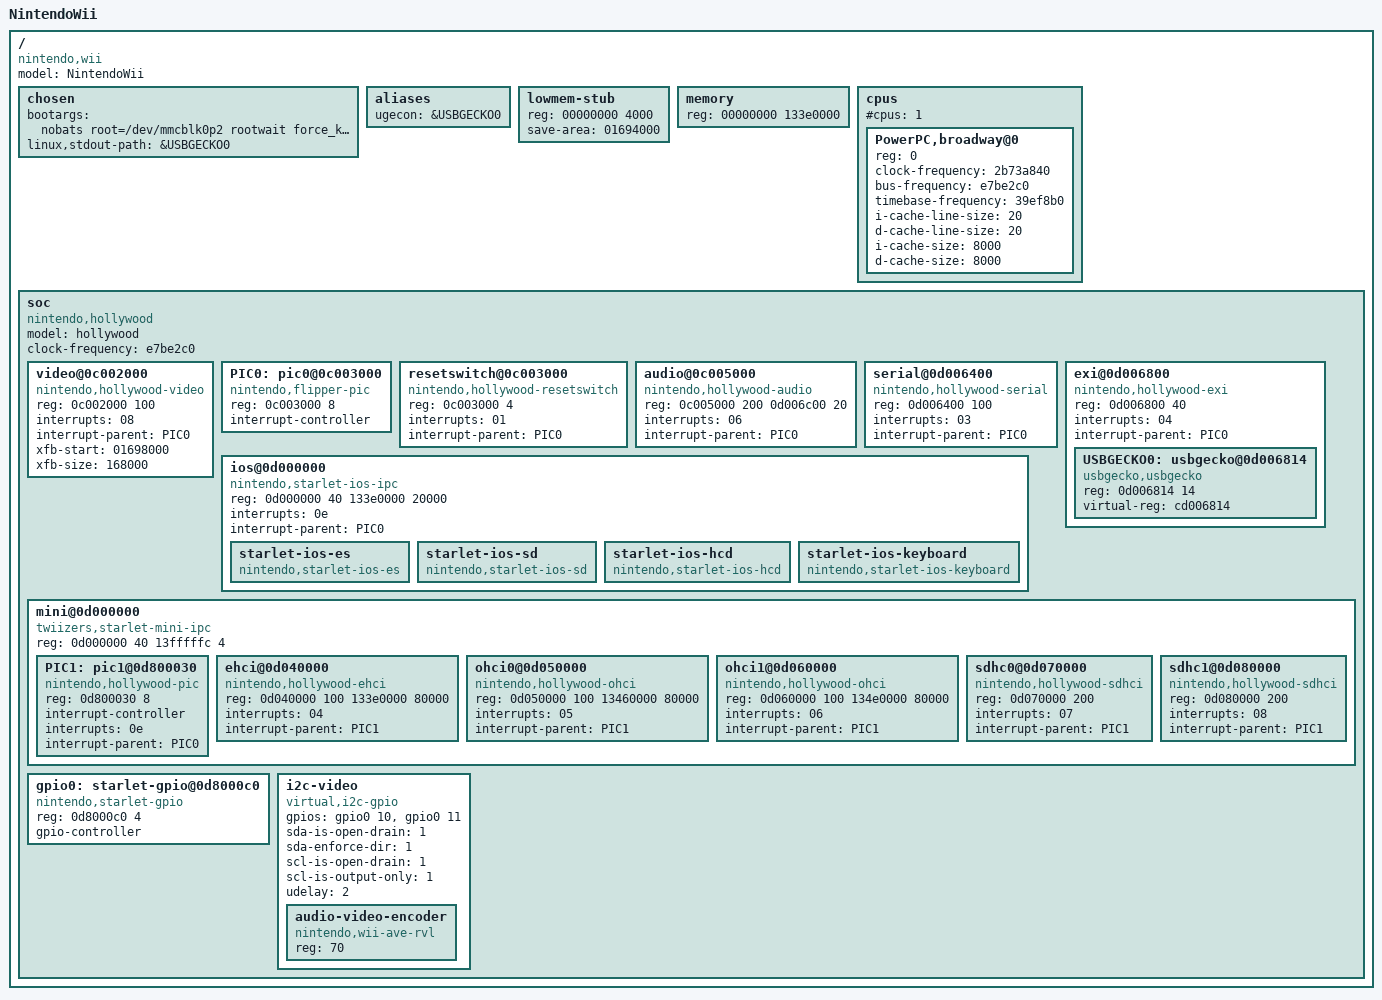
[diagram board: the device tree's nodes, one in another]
/*
 * arch/powerpc/boot/dts/wii.dts
 *
 * Nintendo Wii platform device tree source
 * Copyright (C) 2008-2009 The GameCube Linux Team
 * Copyright (C) 2008,2009 Albert Herranz
 *
 * This program is free software; you can redistribute it and/or
 * modify it under the terms of the GNU General Public License
 * as published by the Free Software Foundation; either version 2
 * of the License, or (at your option) any later version.
 *
 */


/memreserve/ 01694000-01697fff; /* lowmem stub save area */
/memreserve/ 01698000-017fffff;	/* framebuffer, see video@0c002000 */
/memreserve/ 01800000-0fffffff;	/* memory hole */
/memreserve/ 10000000-10003fff;	/* DSP */

/ {
	model = "NintendoWii";
	compatible = "nintendo,wii";
	#address-cells = <1>;
	#size-cells = <1>;

	chosen {
		/* ramdisk */
		/* bootargs = "nobats root=/dev/ram0 video=gcnfb ip=on force_keyboard_port=4"; */

		/* nfsroot */
		/* bootargs = "nobats root=/dev/nfs nfsroot=192.168.001.253:/nfsroot/cube ip=on video=gcnfb:tv=NTSC force_keyboard_port=4"; */

		/* root filesystem on 2nd partition of SD card, whiite style  */
		bootargs = "nobats root=/dev/mmcblk0p2 rootwait force_keyboard_port=4 video=gcnfb:60Hz,tv=NTSC placeholder_for_additional_kernel_options_targetted_at_hexedit_lovers";
		linux,stdout-path = &USBGECKO0;
	};

	aliases {
		ugecon = &USBGECKO0;
	};

	lowmem-stub {
		reg = <00000000 4000>;
		save-area = <01694000>;	/* must be memreserve'd */
	};

	memory {
		device_type = "memory";
		/* mem1 + hole + mem2 - ioh */
		reg = <00000000 133e0000>;
	};

	cpus {
		#cpus = <1>;
		#address-cells = <1>;
		#size-cells = <0>;

		PowerPC,broadway@0 {
			device_type = "cpu";
			reg = <0>;
			clock-frequency = <2b73a840>; /* 729MHz */
			bus-frequency = <e7be2c0>; /* 243MHz core-to-bus 3x */
			timebase-frequency = <39ef8b0>; /* 243MHz / 4 */
			/* Following required by dtc but not used */
			i-cache-line-size = <20>;
			d-cache-line-size = <20>;
			i-cache-size = <8000>;
			d-cache-size = <8000>;
		};
	};

	/* devices contained in the hollywood chipset */
	soc {
		#address-cells = <1>;
		#size-cells = <1>;
		#interrupt-cells = <1>;
		model = "hollywood";
		compatible = "nintendo,hollywood";
		clock-frequency = <e7be2c0>; /* 243MHz */
		ranges = <0c000000 0c000000 00010000
			  0d000000 0d000000 00010000
			  0d040000 0d040000 00050000
			  0d800000 0d800000 00001000
			  133e0000 133e0000 00c20000>;

		video@0c002000 {
			compatible = "nintendo,hollywood-video";
			reg = <0c002000 100>;
			interrupts = <08>;
			interrupt-parent = <&PIC0>;
			xfb-start = <01698000>; /* end-of-mem1 - xfb-size */
			xfb-size = <168000>;	/* 640x576x2 x 2 bytes */
		};

		PIC0: pic0@0c003000 {
			#interrupt-cells = <1>;
			compatible = "nintendo,flipper-pic";
			reg = <0c003000 8>;
			interrupt-controller;
		};

		resetswitch@0c003000 {
			compatible = "nintendo,hollywood-resetswitch";
			reg = <0c003000 4>;
			interrupts = <01>;
			interrupt-parent = <&PIC0>;
		};

		audio@0c005000 {
			compatible = "nintendo,hollywood-audio";
			reg = <0c005000 200	/* DSP */
			       0d006c00 20>;	/* AI */
			interrupts = <06>;
			interrupt-parent = <&PIC0>;
		};

		serial@0d006400 {
			compatible = "nintendo,hollywood-serial";
			reg = <0d006400 100>;
			interrupts = <03>;
			interrupt-parent = <&PIC0>;
		};

		/* External Interface bus */
		exi@0d006800 {
			#address-cells = <1>;
			#size-cells = <1>;
			compatible = "nintendo,hollywood-exi";
			reg = <0d006800 40>;
			interrupts = <04>;
			interrupt-parent = <&PIC0>;

			USBGECKO0: usbgecko@0d006814 {
				compatible = "usbgecko,usbgecko";
				reg = <0d006814 14>;
				virtual-reg = <cd006814>;
			};
		};

		/*
		 * Firmware interfaces accessible through Nintendo IOS IPC.
		 */
		ios@0d000000 {
			compatible = "nintendo,starlet-ios-ipc";
			reg = <0d000000 40	/* IPC */
			       133e0000 20000>;	/* MEM2 ioh 128K */
			interrupts = <0e>;
			interrupt-parent = <&PIC0>;

			starlet-ios-es {
				compatible = "nintendo,starlet-ios-es";
			};

			starlet-ios-sd {
				compatible = "nintendo,starlet-ios-sd";
			};

			starlet-ios-hcd {
				compatible = "nintendo,starlet-ios-hcd";
			};

			starlet-ios-keyboard {
				compatible = "nintendo,starlet-ios-keyboard";
			};
		};

		/*
		 * Hardware accessible through Team Twiizers 'mini' firmware
		 * replacement for Starlet.
		 */
		mini@0d000000 {
			#address-cells = <1>;
			#size-cells = <1>;
			#interrupt-cells = <1>;
			compatible = "twiizers,starlet-mini-ipc";
			reg = <0d000000 40	/* IPC */
			       13fffffc 4>;	/* mini header pointer */

			ranges = <0d040000 0d040000 00050000
				  0d800000 0d800000 00001000
				  133e0000 133e0000 00c20000>;

			PIC1: pic1@0d800030 {
				#interrupt-cells = <1>;
				compatible = "nintendo,hollywood-pic";
				reg = <0d800030 8>;
				interrupt-controller;
				interrupts = <0e>;
				interrupt-parent = <&PIC0>;
			};
			ehci@0d040000 {
				compatible = "nintendo,hollywood-ehci";
				reg = <0d040000 100
				       133e0000 80000>; /* 512 KB */
				interrupts = <04>;
				interrupt-parent = <&PIC1>;
			};
			ohci0@0d050000 {
				compatible = "nintendo,hollywood-ohci";
				reg = <0d050000 100
				       13460000 80000>; /* 512 KB */
				interrupts = <05>;
				interrupt-parent = <&PIC1>;
			};
			ohci1@0d060000 {
				compatible = "nintendo,hollywood-ohci";
				reg = <0d060000 100
				       134e0000 80000>; /* 512 KB */
				interrupts = <06>;
				interrupt-parent = <&PIC1>;
			};
			sdhc0@0d070000 {
				compatible = "nintendo,hollywood-sdhci";
				reg = <0d070000 200>;
				interrupts = <07>;
				interrupt-parent = <&PIC1>;
			};
			sdhc1@0d080000 {
				compatible = "nintendo,hollywood-sdhci";
				reg = <0d080000 200>;
				interrupts = <08>;
				interrupt-parent = <&PIC1>;
			};
		};

		gpio0: starlet-gpio@0d8000c0 {
			compatible = "nintendo,starlet-gpio";
			reg = <0d8000c0 4>;
			gpio-controller;
			#gpio-cells = <2>;
		};

		i2c-video {
			#address-cells = <1>;
			#size-cells = <0>;
		        compatible = "virtual,i2c-gpio";

		        gpios = <&gpio0  10 0 /* 0x10 = 31 - 15 */
		                 &gpio0  11 0 /* 0x11 = 31 - 14 */
				>;
		        sda-is-open-drain = <1>;
		        sda-enforce-dir = <1>;
		        scl-is-open-drain = <1>;
		        scl-is-output-only = <1>;
		        udelay = <2>;

		        audio-video-encoder {
		                compatible = "nintendo,wii-ave-rvl";
		                reg = <70>;
		        };
		};
	};
};

